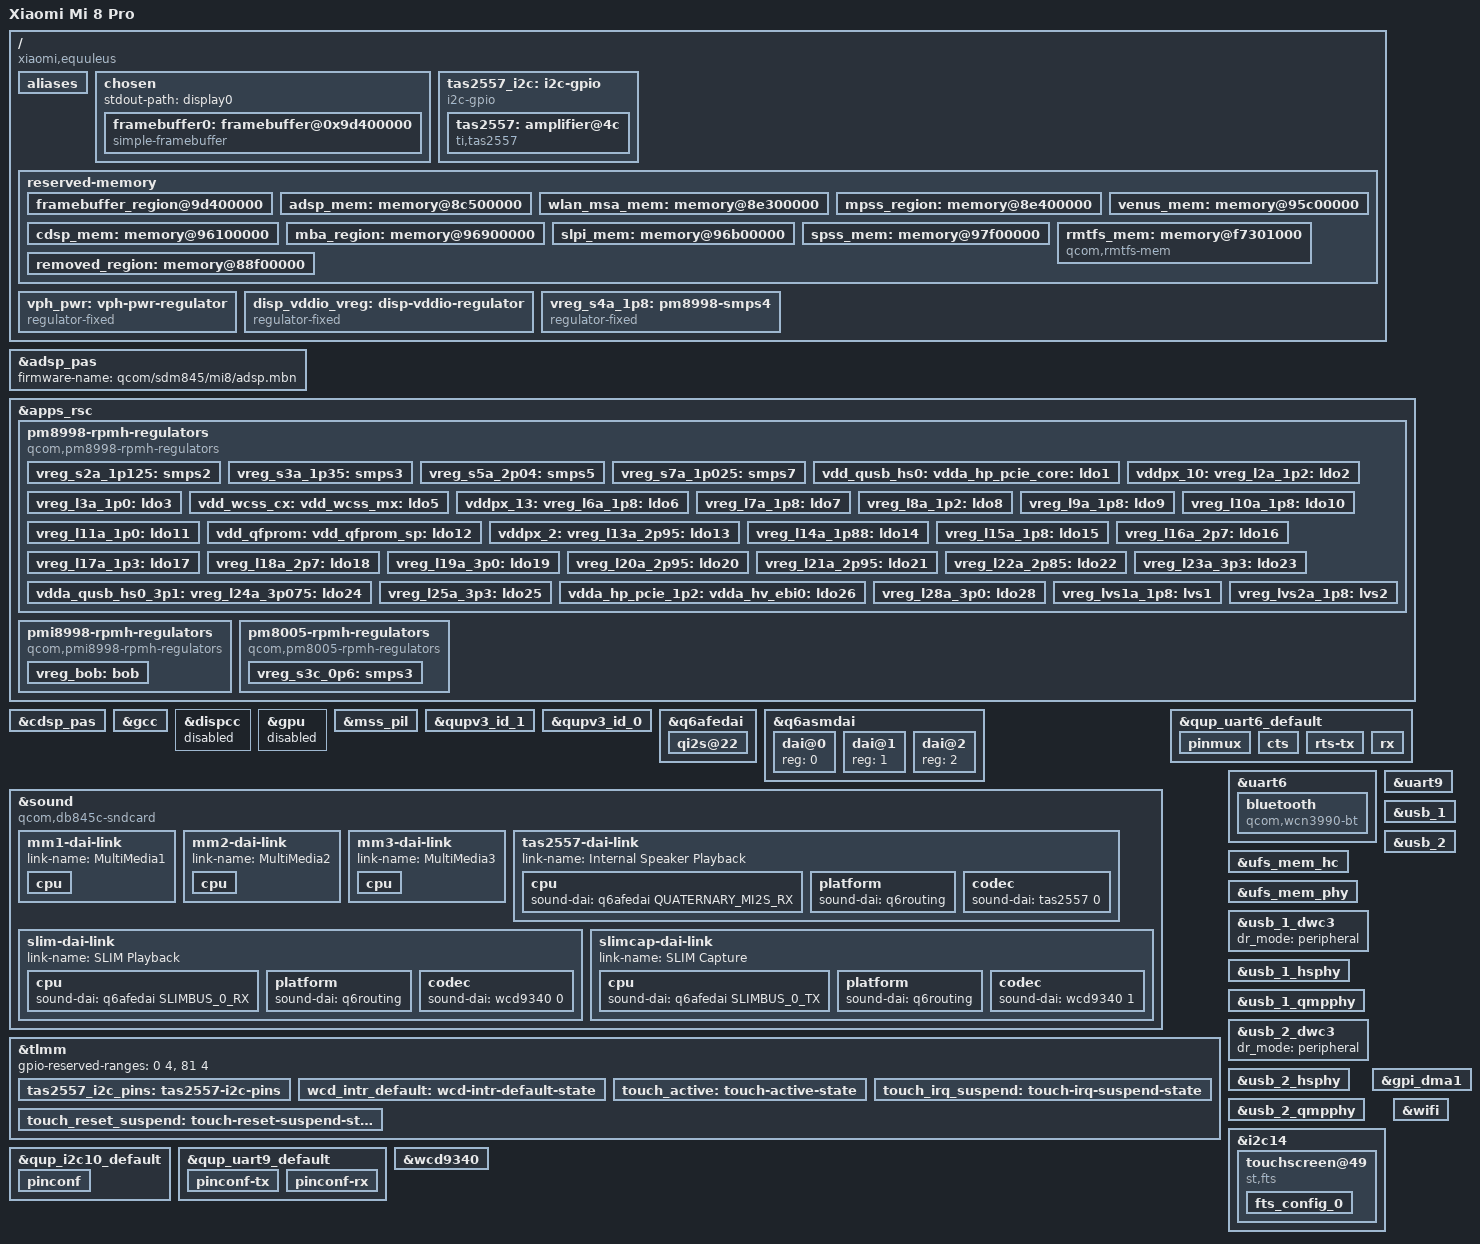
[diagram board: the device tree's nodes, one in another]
// SPDX-License-Identifier: GPL-2.0
/*
 * SDM845 Xiaomi Mi 8 Pro (equuleus) device tree
 *
 * Copyright (c) 2021, The Linux Foundation. All rights reserved.
 */

/dts-v1/;

#include <dt-bindings/gpio/gpio.h>
#include <dt-bindings/regulator/qcom,rpmh-regulator.h>
#include <dt-bindings/sound/qcom,q6afe.h>
#include <dt-bindings/sound/qcom,q6asm.h>
#include "sdm845.dtsi"

/*
 * Delete following upstream (sdm845.dtsi) reserved
 * memory mappings which are different in this device.
 */
/delete-node/ &tz_mem;
/delete-node/ &adsp_mem;
/delete-node/ &wlan_msa_mem;
/delete-node/ &mpss_region;
/delete-node/ &venus_mem;
/delete-node/ &cdsp_mem;
/delete-node/ &mba_region;
/delete-node/ &slpi_mem;
/delete-node/ &spss_mem;
/delete-node/ &rmtfs_mem;

/ {
	model = "Xiaomi Mi 8 Pro";
	compatible = "xiaomi,equuleus", "qcom,sdm845", "qcom,mtp";
	qcom,msm-id = <321 0x20001>;
	qcom,board-id = <79 0>;

	aliases {
		hsuart0 = &uart6;
		serial0 = &uart9;
		display0 = &framebuffer0;
	};

	chosen {
		#address-cells = <2>;
		#size-cells = <2>;
		ranges;

		stdout-path = "display0";

        /* hack: Use framebuffer setup by the bootloader for simplefb. */
		framebuffer0: framebuffer@0x9d400000 {
			compatible = "simple-framebuffer";
			reg = <0x0 0x9d400000 0x0 (1080 * 2248 * 4)>;
			width = <1080>;
			height = <2248>;
			stride = <(1080 * 4)>;
			format = "a8r8g8b8";
		};
	};

	tas2557_i2c: i2c-gpio {
		compatible = "i2c-gpio";
		#address-cells = <1>;
		#size-cells = <0>;
		pinctrl-names = "default";
		pinctrl-0 = <&tas2557_i2c_pins>;

		sda-gpios = <&tlmm 85 (GPIO_ACTIVE_HIGH | GPIO_OPEN_DRAIN)>;
		scl-gpios = <&tlmm 86 (GPIO_ACTIVE_HIGH | GPIO_OPEN_DRAIN)>;
		i2c-gpio,delay-us = <5>;

		tas2557: amplifier@4c {
			compatible = "ti,tas2557";
			reg = <0x4c>;
			#sound-dai-cells = <1>;

			ti,cdc-reset-gpio = <&tlmm 76 GPIO_ACTIVE_HIGH>;
			ti,irq-gpio = <&tlmm 30 GPIO_ACTIVE_HIGH>;
			ti,i2s-bits = <16>;
			ti,bypass-tmax = <0>;
		};
	};

	reserved-memory {

		/* hack: Framebuffer memory region. */
		framebuffer_region@9d400000 {
			reg = <0x0 0x9d400000 0x0 0x02400000>;
			no-map;
		};

		/* Reserved memory changes from downstream */
		adsp_mem: memory@8c500000 {
			reg = <0 0x8c500000 0 0x1e00000>;
			no-map;
		};

		wlan_msa_mem: memory@8e300000 {
			reg = <0 0x8e300000 0 0x100000>;
			no-map;
		};

		mpss_region: memory@8e400000 {
			reg = <0 0x8e400000 0 0x7800000>;
			no-map;
		};

		venus_mem: memory@95c00000 {
			reg = <0 0x95c00000 0 0x500000>;
			no-map;
		};

		cdsp_mem: memory@96100000 {
			reg = <0 0x96100000 0 0x800000>;
			no-map;
		};

		mba_region: memory@96900000 {
			reg = <0 0x96900000 0 0x200000>;
			no-map;
		};

		slpi_mem: memory@96b00000 {
			reg = <0 0x96b00000 0 0x1400000>;
			no-map;
		};

		spss_mem: memory@97f00000 {
			reg = <0 0x97f00000 0 0x100000>;
			no-map;
		};

		/*
		 * The rmtfs memory region in downstream is 'dynamically allocated'
		 * but given the same address every time. Hard code it as this address is
		 * where the modem firmware expects it to be.
		 */
		rmtfs_mem: memory@f7301000 {
			compatible = "qcom,rmtfs-mem";
			reg = <0 0xf7301000 0 0x200000>;
			no-map;

			qcom,client-id = <1>;
			qcom,vmid = <15>;
		};
		
		/*
		 * It seems like reserving the old rmtfs_mem region is also needed to prevent
		 * random crashes which are most likely modem related, more testing needed.
		 */
		removed_region: memory@88f00000 {
			no-map;
			reg = <0 0x88f00000 0 0x200000>;
		};
	};

	vph_pwr: vph-pwr-regulator {
		compatible = "regulator-fixed";
		regulator-name = "vph_pwr";
		regulator-min-microvolt = <3700000>;
		regulator-max-microvolt = <3700000>;
	};

	disp_vddio_vreg: disp-vddio-regulator {
		compatible = "regulator-fixed";
		regulator-name = "disp_vddio_vreg";
		regulator-min-microvolt = <1800000>;
		regulator-max-microvolt = <1800000>;
		startup-delay-us = <4000>;
		gpio = <&tlmm 23 GPIO_ACTIVE_HIGH>;
		enable-active-high;
		regulator-boot-on;
		regulator-always-on;
	};

	/*
	 * Apparently RPMh does not provide support for PM8998 S4 because it
	 * is always-on; model it as a fixed regulator.
	 */
	vreg_s4a_1p8: pm8998-smps4 {
		compatible = "regulator-fixed";
		regulator-name = "vreg_s4a_1p8";

		regulator-min-microvolt = <1800000>;
		regulator-max-microvolt = <1800000>;

		regulator-always-on;
		regulator-boot-on;

		vin-supply = <&vph_pwr>;
	};
};

&adsp_pas {
	status = "okay";
	firmware-name = "qcom/sdm845/mi8/adsp.mbn";
};

&apps_rsc {
	pm8998-rpmh-regulators {
		compatible = "qcom,pm8998-rpmh-regulators";
		qcom,pmic-id = "a";

		vdd-s1-supply = <&vph_pwr>;
		vdd-s2-supply = <&vph_pwr>;
		vdd-s3-supply = <&vph_pwr>;
		vdd-s4-supply = <&vph_pwr>;
		vdd-s5-supply = <&vph_pwr>;
		vdd-s6-supply = <&vph_pwr>;
		vdd-s7-supply = <&vph_pwr>;
		vdd-s8-supply = <&vph_pwr>;
		vdd-s9-supply = <&vph_pwr>;
		vdd-s10-supply = <&vph_pwr>;
		vdd-s11-supply = <&vph_pwr>;
		vdd-s12-supply = <&vph_pwr>;
		vdd-s13-supply = <&vph_pwr>;
		vdd-l1-l27-supply = <&vreg_s7a_1p025>;
		vdd-l2-l8-l17-supply = <&vreg_s3a_1p35>;
		vdd-l3-l11-supply = <&vreg_s7a_1p025>;
		vdd-l4-l5-supply = <&vreg_s7a_1p025>;
		vdd-l6-supply = <&vph_pwr>;
		vdd-l7-l12-l14-l15-supply = <&vreg_s5a_2p04>;
		vdd-l9-supply = <&vreg_bob>;
		vdd-l10-l23-l25-supply = <&vreg_bob>;
		vdd-l13-l19-l21-supply = <&vreg_bob>;
		vdd-l16-l28-supply = <&vreg_bob>;
		vdd-l18-l22-supply = <&vreg_bob>;
		vdd-l20-l24-supply = <&vreg_bob>;
		vdd-l26-supply = <&vreg_s3a_1p35>;
		vin-lvs-1-2-supply = <&vreg_s4a_1p8>;

		vreg_s2a_1p125: smps2 {
			regulator-min-microvolt = <1100000>;
			regulator-max-microvolt = <1100000>;
		};

		vreg_s3a_1p35: smps3 {
			regulator-min-microvolt = <1352000>;
			regulator-max-microvolt = <1352000>;
		};

		vreg_s5a_2p04: smps5 {
			regulator-min-microvolt = <1904000>;
			regulator-max-microvolt = <2040000>;
		};

		vreg_s7a_1p025: smps7 {
			regulator-min-microvolt = <900000>;
			regulator-max-microvolt = <1028000>;
		};

		vdd_qusb_hs0:
		vdda_hp_pcie_core:
		vdda_mipi_csi0_0p9:
		vdda_mipi_csi1_0p9:
		vdda_mipi_csi2_0p9:
		vdda_mipi_dsi0_pll:
		vdda_mipi_dsi1_pll:
		vdda_qlink_lv:
		vdda_qlink_lv_ck:
		vdda_qrefs_0p875:
		vdda_pcie_core:
		vdda_pll_cc_ebi01:
		vdda_pll_cc_ebi23:
		vdda_sp_sensor:
		vdda_ufs1_core:
		vdda_ufs2_core:
		vdda_usb1_ss_core:
		vdda_usb2_ss_core:
		vreg_l1a_0p875: ldo1 {
			regulator-min-microvolt = <880000>;
			regulator-max-microvolt = <880000>;
			regulator-initial-mode = <RPMH_REGULATOR_MODE_HPM>;
		};

		vddpx_10:
		vreg_l2a_1p2: ldo2 {
			regulator-min-microvolt = <1200000>;
			regulator-max-microvolt = <1200000>;
			regulator-initial-mode = <RPMH_REGULATOR_MODE_HPM>;
			regulator-always-on;
		};

		vreg_l3a_1p0: ldo3 {
			regulator-min-microvolt = <1000000>;
			regulator-max-microvolt = <1000000>;
			regulator-initial-mode = <RPMH_REGULATOR_MODE_HPM>;
		};

		vdd_wcss_cx:
		vdd_wcss_mx:
		vdda_wcss_pll:
		vreg_l5a_0p8: ldo5 {
			regulator-min-microvolt = <800000>;
			regulator-max-microvolt = <800000>;
			regulator-initial-mode = <RPMH_REGULATOR_MODE_HPM>;
		};

		vddpx_13:
		vreg_l6a_1p8: ldo6 {
			regulator-min-microvolt = <1856000>;
			regulator-max-microvolt = <1856000>;
			regulator-initial-mode = <RPMH_REGULATOR_MODE_HPM>;
		};

		vreg_l7a_1p8: ldo7 {
			regulator-min-microvolt = <1800000>;
			regulator-max-microvolt = <1800000>;
			regulator-initial-mode = <RPMH_REGULATOR_MODE_HPM>;
		};

		vreg_l8a_1p2: ldo8 {
			regulator-min-microvolt = <1200000>;
			regulator-max-microvolt = <1248000>;
			regulator-initial-mode = <RPMH_REGULATOR_MODE_HPM>;
		};

		vreg_l9a_1p8: ldo9 {
			regulator-min-microvolt = <1704000>;
			regulator-max-microvolt = <2928000>;
			regulator-initial-mode = <RPMH_REGULATOR_MODE_HPM>;
		};

		vreg_l10a_1p8: ldo10 {
			regulator-min-microvolt = <1704000>;
			regulator-max-microvolt = <2928000>;
			regulator-initial-mode = <RPMH_REGULATOR_MODE_HPM>;
		};

		vreg_l11a_1p0: ldo11 {
			regulator-min-microvolt = <1000000>;
			regulator-max-microvolt = <1048000>;
			regulator-initial-mode = <RPMH_REGULATOR_MODE_HPM>;
		};

		vdd_qfprom:
		vdd_qfprom_sp:
		vdda_apc1_cs_1p8:
		vdda_gfx_cs_1p8:
		vdda_qrefs_1p8:
		vdda_qusb_hs0_1p8:
		vddpx_11:
		vreg_l12a_1p8: ldo12 {
			regulator-min-microvolt = <1800000>;
			regulator-max-microvolt = <1800000>;
			regulator-initial-mode = <RPMH_REGULATOR_MODE_HPM>;
		};

		vddpx_2:
		vreg_l13a_2p95: ldo13 {
			regulator-min-microvolt = <1800000>;
			regulator-max-microvolt = <2960000>;
			regulator-initial-mode = <RPMH_REGULATOR_MODE_HPM>;
		};

		vreg_l14a_1p88: ldo14 {
			regulator-min-microvolt = <1800000>;
			regulator-max-microvolt = <1800000>;
			regulator-initial-mode = <RPMH_REGULATOR_MODE_HPM>;
		};

		vreg_l15a_1p8: ldo15 {
			regulator-min-microvolt = <1800000>;
			regulator-max-microvolt = <1800000>;
			regulator-initial-mode = <RPMH_REGULATOR_MODE_HPM>;
		};

		vreg_l16a_2p7: ldo16 {
			regulator-min-microvolt = <2704000>;
			regulator-max-microvolt = <2704000>;
			regulator-initial-mode = <RPMH_REGULATOR_MODE_HPM>;
		};

		vreg_l17a_1p3: ldo17 {
			regulator-min-microvolt = <1304000>;
			regulator-max-microvolt = <1304000>;
			regulator-initial-mode = <RPMH_REGULATOR_MODE_HPM>;
		};

		vreg_l18a_2p7: ldo18 {
			regulator-min-microvolt = <2704000>;
			regulator-max-microvolt = <2960000>;
			regulator-initial-mode = <RPMH_REGULATOR_MODE_HPM>;
		};

		vreg_l19a_3p0: ldo19 {
			regulator-min-microvolt = <2856000>;
			regulator-max-microvolt = <3104000>;
			regulator-initial-mode = <RPMH_REGULATOR_MODE_HPM>;
		};

		vreg_l20a_2p95: ldo20 {
			regulator-min-microvolt = <2704000>;
			regulator-max-microvolt = <2960000>;
			regulator-initial-mode = <RPMH_REGULATOR_MODE_HPM>;
		};

		vreg_l21a_2p95: ldo21 {
			regulator-min-microvolt = <2704000>;
			regulator-max-microvolt = <2960000>;
			regulator-initial-mode = <RPMH_REGULATOR_MODE_HPM>;
		};

		vreg_l22a_2p85: ldo22 {
			regulator-min-microvolt = <2864000>;
			regulator-max-microvolt = <3312000>;
			regulator-initial-mode = <RPMH_REGULATOR_MODE_HPM>;
		};

		vreg_l23a_3p3: ldo23 {
			regulator-min-microvolt = <3000000>;
			regulator-max-microvolt = <3312000>;
			regulator-initial-mode = <RPMH_REGULATOR_MODE_HPM>;
		};

		vdda_qusb_hs0_3p1:
		vreg_l24a_3p075: ldo24 {
			regulator-min-microvolt = <3088000>;
			regulator-max-microvolt = <3088000>;
			regulator-initial-mode = <RPMH_REGULATOR_MODE_HPM>;
		};

		vreg_l25a_3p3: ldo25 {
			regulator-min-microvolt = <3300000>;
			regulator-max-microvolt = <3312000>;
			regulator-initial-mode = <RPMH_REGULATOR_MODE_HPM>;
		};

		vdda_hp_pcie_1p2:
		vdda_hv_ebi0:
		vdda_hv_ebi1:
		vdda_hv_ebi2:
		vdda_hv_ebi3:
		vdda_mipi_csi_1p25:
		vdda_mipi_dsi0_1p2:
		vdda_mipi_dsi1_1p2:
		vdda_pcie_1p2:
		vdda_ufs1_1p2:
		vdda_ufs2_1p2:
		vdda_usb1_ss_1p2:
		vdda_usb2_ss_1p2:
		vreg_l26a_1p2: ldo26 {
			regulator-min-microvolt = <1200000>;
			regulator-max-microvolt = <1200000>;
			regulator-initial-mode = <RPMH_REGULATOR_MODE_HPM>;
		};

		vreg_l28a_3p0: ldo28 {
			regulator-min-microvolt = <2856000>;
			regulator-max-microvolt = <3008000>;
			regulator-initial-mode = <RPMH_REGULATOR_MODE_HPM>;
			regulator-boot-on;
			regulator-always-on;
		};

		vreg_lvs1a_1p8: lvs1 {
			regulator-min-microvolt = <1800000>;
			regulator-max-microvolt = <1800000>;
		};

		vreg_lvs2a_1p8: lvs2 {
			regulator-min-microvolt = <1800000>;
			regulator-max-microvolt = <1800000>;
		};
	};

	pmi8998-rpmh-regulators {
		compatible = "qcom,pmi8998-rpmh-regulators";
		qcom,pmic-id = "b";

		vdd-bob-supply = <&vph_pwr>;

		vreg_bob: bob {
			regulator-min-microvolt = <3312000>;
			regulator-max-microvolt = <3600000>;
			regulator-initial-mode = <RPMH_REGULATOR_MODE_AUTO>;
			regulator-allow-bypass;
		};
	};

	pm8005-rpmh-regulators {
		compatible = "qcom,pm8005-rpmh-regulators";
		qcom,pmic-id = "c";

		vdd-s1-supply = <&vph_pwr>;
		vdd-s2-supply = <&vph_pwr>;
		vdd-s3-supply = <&vph_pwr>;
		vdd-s4-supply = <&vph_pwr>;

		vreg_s3c_0p6: smps3 {
			regulator-min-microvolt = <600000>;
			regulator-max-microvolt = <600000>;
		};
	};
};

&cdsp_pas {
	status = "okay";
};

&gcc {
	protected-clocks = <GCC_QSPI_CORE_CLK>,
			   <GCC_QSPI_CORE_CLK_SRC>,
			   <GCC_QSPI_CNOC_PERIPH_AHB_CLK>,
			   <GCC_LPASS_Q6_AXI_CLK>,
			   <GCC_LPASS_SWAY_CLK>;
};

&dispcc {
	status = "disabled";
};

&gpu {
	status = "disabled";
};

/* Modem/wifi*/
&mss_pil {
	status = "okay";
	firmware-name = "qcom/sdm845/mi8/mba.mbn", "qcom/sdm845/mi8/modem.mbn";
};

&qupv3_id_1 {
	status = "okay";
};

&qupv3_id_0 {
	status = "okay";
};

&q6afedai {
	qi2s@22 {
		reg = <22>;
		qcom,sd-lines = <0>;
	};
};

&q6asmdai {
	dai@0 {
		reg = <0>;
	};

	dai@1 {
		reg = <1>;
	};

	dai@2 {
		reg = <2>;
	};
};

&sound {
	compatible = "qcom,db845c-sndcard";
	model = "Xiaomi Mi 8 Pro";
	pinctrl-names = "default";
	pinctrl-0 = <&quat_mi2s_active &quat_mi2s_sd0_active>;
	audio-routing =
		"RX_BIAS", "MCLK",
		"AMIC1", "MIC BIAS4",
		"AMIC2", "MIC BIAS2",
		"AMIC3", "MIC BIAS1";

	mm1-dai-link {
		link-name = "MultiMedia1";
		cpu {
			sound-dai = <&q6asmdai MSM_FRONTEND_DAI_MULTIMEDIA1>;
		};
	};

	mm2-dai-link {
		link-name = "MultiMedia2";
		cpu {
			sound-dai = <&q6asmdai MSM_FRONTEND_DAI_MULTIMEDIA2>;
		};
	};

	mm3-dai-link {
		link-name = "MultiMedia3";
		cpu {
			sound-dai = <&q6asmdai MSM_FRONTEND_DAI_MULTIMEDIA3>;
		};
	};

	tas2557-dai-link {
		link-name = "Internal Speaker Playback";
		cpu {
			sound-dai = <&q6afedai QUATERNARY_MI2S_RX>;
		};

		platform {
			sound-dai = <&q6routing>;
		};

		codec {
			sound-dai = <&tas2557 0>;
		};
	};

	slim-dai-link {
		link-name = "SLIM Playback";
		cpu {
			sound-dai = <&q6afedai SLIMBUS_0_RX>;
		};

		platform {
			sound-dai = <&q6routing>;
		};

		codec {
			sound-dai = <&wcd9340 0>;
		};
	};

	slimcap-dai-link {
		link-name = "SLIM Capture";
		cpu {
			sound-dai = <&q6afedai SLIMBUS_0_TX>;
		};

		platform {
			sound-dai = <&q6routing>;
		};

		codec {
			sound-dai = <&wcd9340 1>;
		};
	};
};

&qup_uart6_default {
	pinmux {
		pins = "gpio45", "gpio46", "gpio47", "gpio48";
		function = "qup6";
	};

	cts {
		pins = "gpio45";
		bias-disable;
	};

	rts-tx {
		pins = "gpio46", "gpio47";
		drive-strength = <2>;
		bias-disable;
	};

	rx {
		pins = "gpio48";
		bias-pull-up;
	};
};

&tlmm {
	tas2557_i2c_pins: tas2557-i2c-pins {
		pins = "gpio85", "gpio86";
		function = "gpio";
		drive-strength = <2>;
		bias-disable;
	};
};

&uart6 {
	status = "okay";

	bluetooth {
		compatible = "qcom,wcn3990-bt";

		vddio-supply = <&vreg_s4a_1p8>;
		vddxo-supply = <&vreg_l7a_1p8>;
		vddrf-supply = <&vreg_l17a_1p3>;
		vddch0-supply = <&vreg_l25a_3p3>;
		max-speed = <3200000>;
	};
};

&uart9 {
	status = "okay";
};

&ufs_mem_hc {
	status = "okay";

	reset-gpios = <&tlmm 150 GPIO_ACTIVE_LOW>;

	vcc-supply = <&vreg_l20a_2p95>;
	vcc-max-microamp = <600000>;
};

&ufs_mem_phy {
	status = "okay";

	vdda-phy-supply = <&vdda_ufs1_core>;
	vdda-pll-supply = <&vdda_ufs1_1p2>;
};

&usb_1 {
	status = "okay";
};

&usb_1_dwc3 {
	/* Until we have Type C hooked up we'll force this as peripheral. */
	dr_mode = "peripheral";
};

&usb_1_hsphy {
	status = "okay";

	vdd-supply = <&vdda_usb1_ss_core>;
	vdda-pll-supply = <&vdda_qusb_hs0_1p8>;
	vdda-phy-dpdm-supply = <&vdda_qusb_hs0_3p1>;

	qcom,imp-res-offset-value = <8>;
	qcom,hstx-trim-value = <QUSB2_V2_HSTX_TRIM_21_6_MA>;
	qcom,preemphasis-level = <QUSB2_V2_PREEMPHASIS_5_PERCENT>;
	qcom,preemphasis-width = <QUSB2_V2_PREEMPHASIS_WIDTH_HALF_BIT>;
};

&usb_1_qmpphy {
	status = "okay";

	vdda-phy-supply = <&vdda_usb1_ss_1p2>;
	vdda-pll-supply = <&vdda_usb1_ss_core>;
};

&usb_2 {
	status = "okay";
};

&usb_2_dwc3 {
	/*
	 * Though the USB block on SDM845 can support host, there's no vbus
	 * signal for this port on MTP.  Thus (unless you have a non-compliant
	 * hub that works without vbus) the only sensible thing is to force
	 * peripheral mode.
	 */
	dr_mode = "peripheral";
};

&usb_2_hsphy {
	status = "okay";

	vdd-supply = <&vdda_usb2_ss_core>;
	vdda-pll-supply = <&vdda_qusb_hs0_1p8>;
	vdda-phy-dpdm-supply = <&vdda_qusb_hs0_3p1>;

	qcom,imp-res-offset-value = <8>;
	qcom,hstx-trim-value = <QUSB2_V2_HSTX_TRIM_22_8_MA>;
};

&usb_2_qmpphy {
	status = "okay";

	vdda-phy-supply = <&vdda_usb2_ss_1p2>;
	vdda-pll-supply = <&vdda_usb2_ss_core>;
};

&gpi_dma1 {
	status = "okay";
};

/* Touchscreen bring-up: QUPv3 SE14 uses GPI DMA for I2C transfers. */
&i2c14 {
	status = "okay";

	dmas = <&gpi_dma1 0 6 QCOM_GPI_I2C>,
	       <&gpi_dma1 1 6 QCOM_GPI_I2C>;
	dma-names = "tx", "rx";

	touchscreen@49 {
		compatible = "st,fts";
		reg = <0x49>;
		interrupt-parent = <&tlmm>;
		interrupts = <31 IRQ_TYPE_LEVEL_LOW>;
		pinctrl-names = "pmx_ts_active", "pmx_ts_suspend";
		pinctrl-0 = <&touch_active>;
		pinctrl-1 = <&touch_irq_suspend &touch_reset_suspend>;
		vdd-supply = <&disp_vddio_vreg>;
		avdd-supply = <&vreg_l28a_3p0>;
		fts,pwr-reg-name = "avdd";
		fts,bus-reg-name = "vdd";
		fts,irq-gpio = <&tlmm 31 GPIO_ACTIVE_LOW>;
		fts,reset-gpio-enable;
		fts,reset-gpio = <&tlmm 32 GPIO_ACTIVE_HIGH>;
		fts,irq-flags = <0x2008>;
		fts,x-max = <1080>;
		fts,y-max = <2248>;
		fts,config-array-size = <1>;
		fts,default-fw-name = "st_fts_e8.ftb";

		fts_config_0 {
			fts,tp-vendor = <0x48>;
			fts,fw-name = "st_fts_e8.ftb";
			fts,limit-name = "stm_fts_production_limits.csv";
		};
	};
};

&wifi {
	status = "okay";
	vdd-0.8-cx-mx-supply = <&vreg_l5a_0p8>;
	vdd-1.8-xo-supply = <&vreg_l7a_1p8>;
	vdd-1.3-rfa-supply = <&vreg_l17a_1p3>;
	vdd-3.3-ch0-supply = <&vreg_l25a_3p3>;
	vdd-3.3-ch1-supply = <&vreg_l23a_3p3>;
	qcom,ath10k-calibration-variant = "xiaomi_beryllium";
	qcom,snoc-host-cap-skip-quirk;
};

/* PINCTRL - additions to nodes defined in sdm845.dtsi */

&qup_i2c10_default {
	pinconf {
		pins = "gpio55", "gpio56";
		drive-strength = <2>;
		bias-disable;
	};
};

&qup_uart9_default {
	pinconf-tx {
		pins = "gpio4";
		drive-strength = <2>;
		bias-disable;
	};

	pinconf-rx {
		pins = "gpio5";
		drive-strength = <2>;
		bias-pull-up;
	};
};

&tlmm {
	gpio-reserved-ranges = <0 4>, <81 4>;

	wcd_intr_default: wcd-intr-default-state {
		pins = "gpio54";
		function = "gpio";
		input-enable;
		bias-pull-down;
		drive-strength = <2>;
	};

	touch_active: touch-active-state {
		pins = "gpio31", "gpio32";
		function = "gpio";
		drive-strength = <16>;
		bias-pull-up;
	};

	touch_irq_suspend: touch-irq-suspend-state {
		pins = "gpio31";
		function = "gpio";
		drive-strength = <2>;
		bias-disable;
	};

	touch_reset_suspend: touch-reset-suspend-state {
		pins = "gpio32";
		function = "gpio";
		drive-strength = <2>;
		bias-disable;
	};
};

&wcd9340 {
	pinctrl-0 = <&wcd_intr_default>;
	pinctrl-names = "default";
	clock-names = "extclk";
	clocks = <&rpmhcc RPMH_LN_BB_CLK2>;
	reset-gpios = <&tlmm 64 GPIO_ACTIVE_HIGH>;
	vdd-buck-supply = <&vreg_s4a_1p8>;
	vdd-buck-sido-supply = <&vreg_s4a_1p8>;
	vdd-tx-supply = <&vreg_s4a_1p8>;
	vdd-rx-supply = <&vreg_s4a_1p8>;
	vdd-io-supply = <&vreg_s4a_1p8>;
	qcom,micbias1-microvolt = <2700000>;
	qcom,micbias2-microvolt = <1800000>;
	qcom,micbias3-microvolt = <2700000>;
	qcom,micbias4-microvolt = <2700000>;
};
